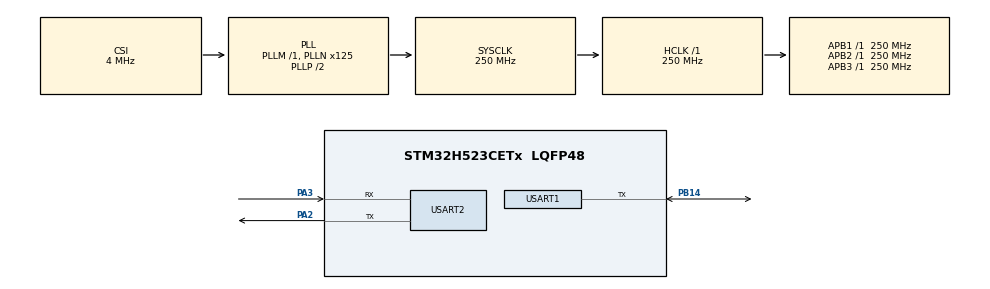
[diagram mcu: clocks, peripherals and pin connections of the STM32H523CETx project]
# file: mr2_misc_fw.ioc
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CORTEX_M33_NS.userName=CORTEX_M33
Mcu.Family=STM32H5
Mcu.Name=STM32H523CETx
Mcu.Package=LQFP48
NVIC.PriorityGroup=NVIC_PRIORITYGROUP_4
NVIC.USART1_IRQn=true\:0\:0\:false\:false\:true\:true\:true\:true
PA13(JTMS/SWDIO).Mode=Serial_Wire
PA13(JTMS/SWDIO).Signal=DEBUG_JTMS-SWDIO
PA14(JTCK/SWCLK).Mode=Serial_Wire
PA14(JTCK/SWCLK).Signal=DEBUG_JTCK-SWCLK
PA2.Mode=Asynchronous
PA2.Signal=USART2_TX
PA3.Mode=Asynchronous
PA3.Signal=USART2_RX
PB14.GPIO_ModeDefaultOD=GPIO_MODE_AF_PP
PB14.GPIO_PuPd=GPIO_NOPULL
PB14.Mode=Half_duplex(single_wire_mode)
PB14.Signal=USART1_TX
PC14-OSC32_IN(OSC32_IN).Mode=LSE-External-Oscillator
PC14-OSC32_IN(OSC32_IN).Signal=RCC_OSC32_IN
PC15-OSC32_OUT(OSC32_OUT).Mode=LSE-External-Oscillator
PC15-OSC32_OUT(OSC32_OUT).Signal=RCC_OSC32_OUT
PH0-OSC_IN(PH0).Mode=HSE-External-Oscillator
PH0-OSC_IN(PH0).Signal=RCC_OSC_IN
PH1-OSC_OUT(PH1).Mode=HSE-External-Oscillator
PH1-OSC_OUT(PH1).Signal=RCC_OSC_OUT
ProjectManager.HeapSize=0x200
ProjectManager.StackSize=0x400
ProjectManager.TargetToolchain=CMake
RCC.ADCFreq_Value=250000000
RCC.AHBFreq_Value=250000000
RCC.APB1Freq_Value=250000000
RCC.APB1TimFreq_Value=250000000
RCC.APB2Freq_Value=250000000
RCC.APB2TimFreq_Value=250000000
RCC.APB3Freq_Value=250000000
RCC.CSI_VALUE=4000000
RCC.CortexFreq_Value=250000000
RCC.EPOD_VALUE=4000000
RCC.HCLKFreq_Value=250000000
RCC.HSE_VALUE=8000000
RCC.HSI48_VALUE=48000000
RCC.HSI_VALUE=64000000
RCC.LSIRC_VALUE=32000
RCC.PLL2FRACN=0
RCC.PLL3FRACN=0
RCC.PLLFRACN=0
RCC.PLLN=125
RCC.SYSCLKFreq_VALUE=250000000
RCC.SYSCLKSource=RCC_SYSCLKSOURCE_PLLCLK
RCC.USBFreq_Value=48000000
RCC.VCOOutputFreq_Value=500000000
USART1.BaudRate=9600
USART1.FIFOMode=FIFOMODE_ENABLE
USART1.Parity=PARITY_EVEN
USART1.RxPinLevelInvertParam=ADVFEATURE_RXINV_ENABLE
USART1.TxPinLevelInvertParam=ADVFEATURE_TXINV_ENABLE
USART1.VirtualMode-Half_duplex(single_wire_mode)=VM_ASYNC
USART1.WordLength=WORDLENGTH_9B
USART2.VirtualMode-Asynchronous=VM_ASYNC
VP_BOOTPATH_VS_BOOTPATH.Mode=BP_Activate
VP_CORTEX_M33_NS_VS_Hclk.Mode=Hclk_Mode
VP_ICACHE_VS_ICACHE.Mode=DirectMappedCache
VP_MEMORYMAP_VS_MEMORYMAP.Mode=CurAppReg
VP_PWR_VS_LPOM.Mode=PowerOptimisation
VP_PWR_VS_SECSignals.Mode=Security/Privilege
board=custom

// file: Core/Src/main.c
/* USER CODE BEGIN Header */
/* USER CODE END Header */
#include "main.h"

/* USER CODE BEGIN Includes */
#include "battery.h"
/* USER CODE END Includes */

UART_HandleTypeDef huart1;
UART_HandleTypeDef huart2;

void SystemClock_Config(void);
static void MX_GPIO_Init(void);
static void MX_USART1_UART_Init(void);
static void MX_USART2_UART_Init(void);
static void MX_ICACHE_Init(void);

int main(void)
{

  /* MCU Configuration--------------------------------------------------------*/

  /* Reset of all peripherals, Initializes the Flash interface and the Systick. */
  HAL_Init();

  /* Configure the system clock */
  SystemClock_Config();

  /* Initialize all configured peripherals */
  MX_GPIO_Init();
  MX_USART1_UART_Init();
  MX_USART2_UART_Init();
  MX_ICACHE_Init();
  /* USER CODE BEGIN 2 */
  battery_init(&huart1, &huart2);
  /* USER CODE END 2 */

  /* Infinite loop */
  /* USER CODE BEGIN WHILE */
  while (1) {
    battery_task();
    // Light cooperative delay; state machine uses HAL_GetTick for timing.
    // HAL_Delay(1);
  }
    /* USER CODE END WHILE */

}

void SystemClock_Config(void)
{
  RCC_OscInitTypeDef RCC_OscInitStruct = {0};
  RCC_ClkInitTypeDef RCC_ClkInitStruct = {0};

  /** Configure the main internal regulator output voltage
  */
  __HAL_PWR_VOLTAGESCALING_CONFIG(PWR_REGULATOR_VOLTAGE_SCALE0);

  while(!__HAL_PWR_GET_FLAG(PWR_FLAG_VOSRDY)) {}

  /** Initializes the RCC Oscillators according to the specified parameters
  * in the RCC_OscInitTypeDef structure.
  */
  RCC_OscInitStruct.OscillatorType = RCC_OSCILLATORTYPE_CSI;
  RCC_OscInitStruct.CSIState = RCC_CSI_ON;
  RCC_OscInitStruct.CSICalibrationValue = RCC_CSICALIBRATION_DEFAULT;
  RCC_OscInitStruct.PLL.PLLState = RCC_PLL_ON;
  RCC_OscInitStruct.PLL.PLLSource = RCC_PLL1_SOURCE_CSI;
  RCC_OscInitStruct.PLL.PLLM = 1;
  RCC_OscInitStruct.PLL.PLLN = 125;
  RCC_OscInitStruct.PLL.PLLP = 2;
  RCC_OscInitStruct.PLL.PLLQ = 2;
  RCC_OscInitStruct.PLL.PLLR = 2;
  RCC_OscInitStruct.PLL.PLLRGE = RCC_PLL1_VCIRANGE_2;
  RCC_OscInitStruct.PLL.PLLVCOSEL = RCC_PLL1_VCORANGE_WIDE;
  RCC_OscInitStruct.PLL.PLLFRACN = 0;
  if (HAL_RCC_OscConfig(&RCC_OscInitStruct) != HAL_OK)
  {
    Error_Handler();
  }

  /** Initializes the CPU, AHB and APB buses clocks
  */
  RCC_ClkInitStruct.ClockType = RCC_CLOCKTYPE_HCLK|RCC_CLOCKTYPE_SYSCLK
                              |RCC_CLOCKTYPE_PCLK1|RCC_CLOCKTYPE_PCLK2
                              |RCC_CLOCKTYPE_PCLK3;
  RCC_ClkInitStruct.SYSCLKSource = RCC_SYSCLKSOURCE_PLLCLK;
  RCC_ClkInitStruct.AHBCLKDivider = RCC_SYSCLK_DIV1;
  RCC_ClkInitStruct.APB1CLKDivider = RCC_HCLK_DIV1;
  RCC_ClkInitStruct.APB2CLKDivider = RCC_HCLK_DIV1;
  RCC_ClkInitStruct.APB3CLKDivider = RCC_HCLK_DIV1;

  if (HAL_RCC_ClockConfig(&RCC_ClkInitStruct, FLASH_LATENCY_5) != HAL_OK)
  {
    Error_Handler();
  }

  /** Configure the programming delay
  */
  __HAL_FLASH_SET_PROGRAM_DELAY(FLASH_PROGRAMMING_DELAY_2);
}

static void MX_ICACHE_Init(void)
{

  /** Enable instruction cache in 1-way (direct mapped cache)
  */
  if (HAL_ICACHE_ConfigAssociativityMode(ICACHE_1WAY) != HAL_OK)
  {
    Error_Handler();
  }
  if (HAL_ICACHE_Enable() != HAL_OK)
  {
    Error_Handler();
  }

}

static void MX_USART1_UART_Init(void)
{

  huart1.Instance = USART1;
  huart1.Init.BaudRate = 9600;
  huart1.Init.WordLength = UART_WORDLENGTH_9B;
  huart1.Init.StopBits = UART_STOPBITS_1;
  huart1.Init.Parity = UART_PARITY_EVEN;
  huart1.Init.Mode = UART_MODE_TX_RX;
  huart1.Init.HwFlowCtl = UART_HWCONTROL_NONE;
  huart1.Init.OverSampling = UART_OVERSAMPLING_16;
  huart1.Init.OneBitSampling = UART_ONE_BIT_SAMPLE_DISABLE;
  huart1.Init.ClockPrescaler = UART_PRESCALER_DIV1;
  huart1.AdvancedInit.AdvFeatureInit = UART_ADVFEATURE_TXINVERT_INIT|UART_ADVFEATURE_RXINVERT_INIT;
  huart1.AdvancedInit.TxPinLevelInvert = UART_ADVFEATURE_TXINV_ENABLE;
  huart1.AdvancedInit.RxPinLevelInvert = UART_ADVFEATURE_RXINV_ENABLE;
  if (HAL_HalfDuplex_Init(&huart1) != HAL_OK)
  {
    Error_Handler();
  }
  if (HAL_UARTEx_SetTxFifoThreshold(&huart1, UART_TXFIFO_THRESHOLD_1_8) != HAL_OK)
  {
    Error_Handler();
  }
  if (HAL_UARTEx_SetRxFifoThreshold(&huart1, UART_RXFIFO_THRESHOLD_1_8) != HAL_OK)
  {
    Error_Handler();
  }
  if (HAL_UARTEx_EnableFifoMode(&huart1) != HAL_OK)
  {
    Error_Handler();
  }

}

static void MX_USART2_UART_Init(void)
{

  huart2.Instance = USART2;
  huart2.Init.BaudRate = 115200;
  huart2.Init.WordLength = UART_WORDLENGTH_8B;
  huart2.Init.StopBits = UART_STOPBITS_1;
  huart2.Init.Parity = UART_PARITY_NONE;
  huart2.Init.Mode = UART_MODE_TX_RX;
  huart2.Init.HwFlowCtl = UART_HWCONTROL_NONE;
  huart2.Init.OverSampling = UART_OVERSAMPLING_16;
  huart2.Init.OneBitSampling = UART_ONE_BIT_SAMPLE_DISABLE;
  huart2.Init.ClockPrescaler = UART_PRESCALER_DIV1;
  huart2.AdvancedInit.AdvFeatureInit = UART_ADVFEATURE_NO_INIT;
  if (HAL_UART_Init(&huart2) != HAL_OK)
  {
    Error_Handler();
  }
  if (HAL_UARTEx_SetTxFifoThreshold(&huart2, UART_TXFIFO_THRESHOLD_1_8) != HAL_OK)
  {
    Error_Handler();
  }
  if (HAL_UARTEx_SetRxFifoThreshold(&huart2, UART_RXFIFO_THRESHOLD_1_8) != HAL_OK)
  {
    Error_Handler();
  }
  if (HAL_UARTEx_DisableFifoMode(&huart2) != HAL_OK)
  {
    Error_Handler();
  }

}

static void MX_GPIO_Init(void)
{

  /* GPIO Ports Clock Enable */
  __HAL_RCC_GPIOC_CLK_ENABLE();
  __HAL_RCC_GPIOH_CLK_ENABLE();
  __HAL_RCC_GPIOA_CLK_ENABLE();
  __HAL_RCC_GPIOB_CLK_ENABLE();

}

void Error_Handler(void)
{
}
